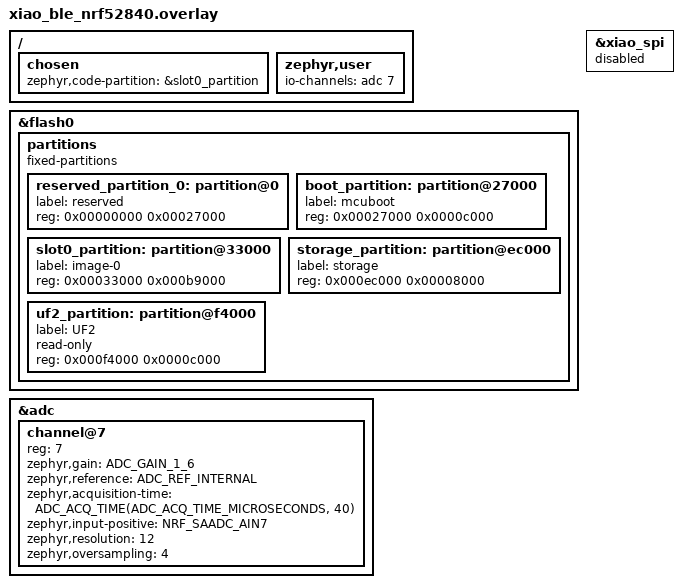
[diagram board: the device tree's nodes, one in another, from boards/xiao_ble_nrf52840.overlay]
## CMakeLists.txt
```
#
# Copyright (c) 2025 Nordic Semiconductor ASA
#
# SPDX-License-Identifier: LicenseRef-Nordic-5-Clause
#

cmake_minimum_required(VERSION 3.20.0)

find_package(Zephyr REQUIRED HINTS $ENV{ZEPHYR_BASE})
project(beacon)

# Board-specific battery path. Devicetree + Kconfig per board come from
# boards/<board>.overlay and boards/<board>.conf (picked up by Zephyr).
if(BOARD STREQUAL "xiao_ble" OR BOARD STREQUAL "promicro_nrf52840")
  set(BMT_BATTERY_SRC src/bmt_battery_${BOARD}.c)
else()
  message(FATAL_ERROR "Unsupported board '${BOARD}'. Use xiao_ble/nrf52840 or promicro_nrf52840/nrf52840/uf2.")
endif()

target_sources(app PRIVATE
    src/main.c
    src/bmt_auth.c
    src/bmt_beacon.c
    src/bmt_battery.c
    ${BMT_BATTERY_SRC}
)

# Wire protocol shared with the ESP-IDF apps (plain C header).
target_include_directories(app PRIVATE ${CMAKE_CURRENT_SOURCE_DIR}/../../components/bmt_protocol)
```

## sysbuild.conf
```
# [SECURITY] MCUboot - the Zephyr counterpart to Secure Boot V2 on ESP32 Tag.
# Single-slot mode: MCUboot only verifies the signature and boots
# slot0_partition. OTA over BLE is not supported yet (updates = re-flash
# the whole UF2 via the pre-installed Adafruit bootloader, see
# boards/<board>.overlay for why the layout is this way).
SB_CONFIG_BOOTLOADER_MCUBOOT=y
SB_CONFIG_MCUBOOT_MODE_SINGLE_APP=y
SB_CONFIG_BOOT_SIGNATURE_TYPE_ECDSA_P256=y
SB_CONFIG_BOOT_SIGNATURE_KEY_FILE="../../keys/bmt_tag_ecdsa_p256.pem"
```

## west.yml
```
# Freestanding Zephyr application manifest. Lets `west init -l .` set up
# a workspace that pulls in upstream Zephyr next to this app, without
# requiring the whole nRF Connect SDK.
manifest:
  self:
    path: apps/beacon_nrf52840
  remotes:
    - name: zephyrproject
      url-base: https://github.com/zephyrproject-rtos
  projects:
    - name: zephyr
      remote: zephyrproject
      revision: v4.0.0
      import:
        name-allowlist:
          - hal_nordic
          - mcuboot
          - cmsis
          - segger
          - tinycrypt
```

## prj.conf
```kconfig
# Common to every board. Board-specific Kconfig lives in
# boards/<board>.conf (merged automatically by Zephyr).

CONFIG_BT=y
CONFIG_BT_DEVICE_NAME="Test beacon"

# PSA Crypto (HMAC-SHA256) - needed by bmt_auth for epoch key rotation.
CONFIG_PSA_CRYPTO=y
CONFIG_PSA_WANT_ALG_HMAC=y
CONFIG_PSA_WANT_ALG_SHA_256=y
CONFIG_PSA_WANT_KEY_TYPE_HMAC=y

# [POWER] Drop the radio TX power from the default 0 dBm to -4 dBm. Cuts
# current at TX (also reduces the current pulse amplitude through the
# diode / cap - see the CR2032 sag discussion in README), at the cost of
# slightly shorter range - re-verify real-world distance after flashing.
CONFIG_BT_CTLR_TX_PWR_MINUS_4=y

# [POWER] Read the battery via the SAADC - channel per board in
# boards/<board>.overlay, conversion in src/bmt_battery_<board>.c.
CONFIG_ADC=y

# =====================================================================
# [POWER] Disable USB + CONSOLE + LOG - the largest single saving (~0.7-0.8 mA)
# =====================================================================
#
# Both boards use USB CDC-ACM as their console (no dedicated UART for
# debug), so just having CONFIG_CONSOLE=y drags in the full USB device
# stack and keeps it running forever: CONFIG_USB_DEVICE_STACK_NEXT +
# CONFIG_UDC_NRF. Because CONFIG_PM_DEVICE is not enabled, nothing
# suspends them -> current is drawn continuously EVEN AFTER the USB
# cable is unplugged.
#
# Measured on ProMicro (running from battery, USB unplugged, DT-9205A on
# the 200 mA range):
#   Full firmware (with USB / log)         1.7 mA
#   Empty firmware (no USB / log / BLE)    1.0 mA   <- the 0.7 mA diff is USB
#   Empty firmware + P0.13 LOW             0.9 mA   <- hardware floor, nothing to do
#
# DEBUG NOTE: turning this off means NO COM port and NO log. When you need
# logs, build with debug.conf to bring them back (see README, Build).
#
# Trying just CONFIG_LOG=n does NOT help - it only stops printing; the USB
# stack still initialises and runs. You must disable the console for the
# USB stack to actually be dropped from the build.
# THIS is the right switch (one line, instead of picking off each symbol).
# See zephyr/boards/common/usb/Kconfig.cdc_acm_serial.defconfig - the whole
#     if BOARD_SERIAL_BACKEND_CDC_ACM
#         config SERIAL                          default y
#         config CONSOLE                         default y
#         config USB_DEVICE_STACK_NEXT           default y if !MCUBOOT
#         config CDC_ACM_SERIAL_INITIALIZE_AT_BOOT  default y if !MCUBOOT
# block hangs off this switch, so disabling it drops the whole cluster.
#
# Turn off BOTH lines at the same time (do not split): CONFIG_LOG=n is
# what drops log_backend_uart.c from the build. Picking off
# CONFIG_CONSOLE / UART_CONSOLE / SERIAL=n one at a time does NOT work -
# .config still has USB_DEVICE_STACK_NEXT=y and UDC_NRF=y, and the build
# fails with "undefined reference __device_dts_ord_N" because the log /
# CDC-ACM backend is still compiled while its device was dropped from
# devicetree (hit on both boards).
CONFIG_BOARD_SERIAL_BACKEND_CDC_ACM=n
CONFIG_LOG=n
```

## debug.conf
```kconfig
# =====================================================================
# DEBUG BUILD - re-enable console / log over USB CDC-ACM
# =====================================================================
#
# prj.conf (production) DISABLES USB + console + log because they draw
# ~0.7-0.8 mA continuously even after the USB cable is unplugged - 
# see the full explanation in prj.conf.
#
# This file re-enables them so you can read logs for debugging. DO NOT
# USE FOR CURRENT MEASUREMENT: the reading will be ~0.7-0.8 mA higher
# than the real firmware.
#
# Build command (pick the board):
#   west build -b xiao_ble/nrf52840 -d build_debug . --pristine \
#       -- "-Dbeacon_nrf52840_EXTRA_CONF_FILE=debug.conf"
#   west build -b promicro_nrf52840/nrf52840/uf2 -d build_debug . --pristine \
#       -- "-Dbeacon_nrf52840_EXTRA_CONF_FILE=debug.conf"
#
# (The "beacon_nrf52840_" prefix is required - this is a sysbuild
#  multi-image build; without the prefix CMake configure will fail.)

# Re-enable the switch that prj.conf turned off. This drags in the
# whole cluster: SERIAL, CONSOLE, UART_CONSOLE, USB_DEVICE_STACK_NEXT,
# CDC_ACM_SERIAL_INITIALIZE_AT_BOOT (see prj.conf for the detail).
#
# NOTE: setting only CONFIG_CONSOLE=y / SERIAL=y without this line is
# USELESS - the console comes up but there is no UART device to send
# output to, so no COM port appears. (Been caught by this once on
# ProMicro.)
CONFIG_BOARD_SERIAL_BACKEND_CDC_ACM=y
CONFIG_LOG=y

# Bump the USB buffer pool to avoid "udc: Failed to allocate net_buf N"
# when USB control transactions and CDC-ACM log traffic overlap (after
# SUSPEND / RESUME).
CONFIG_UDC_BUF_POOL_SIZE=4096
CONFIG_UDC_BUF_COUNT=32
```

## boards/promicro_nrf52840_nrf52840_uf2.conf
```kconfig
# ProMicro nRF52840 - merged on top of prj.conf.

# [POWER] Turn off the soft switch that feeds power to the external VCC pin
# (P0.13) - saves ~0.1 mA. Needs the GPIO driver. See src/main.c and the
# overlay for the schematic detail.
CONFIG_GPIO=y

# =====================================================================
# [POWER] KEY DIFFERENCE VS XIAO - DC/DC regulator
# =====================================================================
#
# The nRF52840 has TWO separate DC/DC regulators for two power architectures:
#
#  - REG1 ("normal voltage"): used when VDD is fed by an external LDO that
#    has already stepped the rail down. This is the XIAO case (battery ->
#    BQ25101 -> LDO SGM2040 3.3 V). The XIAO board devicetree ships both
#    regulators enabled:
#         &reg0 { status = "okay"; };
#         &reg1 { regulator-initial-mode = <NRF5X_REG_MODE_DCDC>; };
#    plus the L3 10 uH inductor between DCC / DEC4.
#
#  - REG0 ("high voltage"): used when the battery wires directly into VDDH
# - the ProMicro / nice!nano v2 architecture.
#
# The ProMicro board in Zephyr does NOT configure reg0 / reg1 at all, so both
# stay at their defaults (REG1 in LDO mode, not DCDC).
#
# NOTE: the two legacy Kconfig symbols (CONFIG_SOC_DCDC_NRF52X / _HV) are
# DEPRECATED in this Zephyr version - DCDC must be enabled through
# DEVICETREE as shown above, not through prj.conf. (The
# CONFIG_BOARD_ENABLE_DCDC_HV symbol some ZMK guides mention is a ZMK-only
# thing and does not exist in upstream Zephyr.)
#
# NOT enabled in the initial version - DELIBERATE:
#   1) Cannot confirm this clone board has the inductor DCDC needs.
#   2) Real-world data from the ZMK community (issue zmkfirmware/zmk#2990)
#      shows enabling DC/DC HV mode on this class of board can INCREASE
#      current:
#         - Official nice!nano: +0.12-0.48 mA standby (up 20-25%)
#         - Clone boards: +1.30-1.32 mA (!!)
#      Suspicion: clones drop the inductor, so the switcher misbehaves
#      and draws more than the LDO would.
#
# => PLAN: measure current at the default first, then try enabling DCDC via
#    devicetree and remeasure. Only keep it if the numbers actually improve.

# =====================================================================
# [POWER] [TODO - not done, deliberate] Turn off unused peripherals
# =====================================================================
# The ProMicro board enables more peripherals than XIAO: i2c0, i2c1, pwm0,
# spi2, uart0 (see promicro_nrf52840_nrf52840_common.dts). This beacon app
# uses none of them, so disabling in principle would save a bit more.
#
# NOT done in the initial version: first want a WORKING image plus baseline
# current measurement, then disable one at a time AND remeasure to confirm
# each step. (Lesson from the XIAO variant: disabling SPI2 was thought to
# have hung the board, wasted hours debugging - the real culprit was
# flashing an unsigned app image. Since then, verify one config change at
# a time; don't change many things at once.)
#
# WATCH OUT: pwm0 is referenced by the "pwmleds" node (red_pwm_led);
# disabling pwm0 without handling that node will break the build.
```

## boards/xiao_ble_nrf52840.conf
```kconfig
# XIAO nRF52840 - merged on top of prj.conf. No extra symbols needed.
#
# [POWER] APPROACH A (continuous low-power advertising):
#  - CPU auto-sleeps (System ON idle) between transmits: Zephyr's idle
#    thread handles this - no config needed.
#  - DC/DC regulator: ALREADY ENABLED via the board devicetree (reg1 =
#    DCDC mode); nRF52's soc.c reads that property and calls
#    nrf_power_dcdcen_set(true) at boot, so NO extra config here.
#    (Verified against soc/nordic/nrf52/soc.c.)
#  - 1 s interval (bmt_config.h) and TX -4 dBm already set.
# => Approach A is close to optimal by construction; real current
#    measurement needs a Power Profiler (PPK2).
```

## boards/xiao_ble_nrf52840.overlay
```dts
/*
 * [SECURITY] MCUboot partition layout - Tag nRF52840.
 *
 * XIAO nRF52840 ships from the factory with the Adafruit UF2
 * bootloader (no SWD / J-Link is exposed; the only way to reflash
 * is UF2 mass storage). That bootloader lives at a FIXED high
 * address (0xF4000-0x100000, see nrf52840_partition_uf2_sdv7.dtsi
 * in Zephyr) and is jumped to directly by the CPU from
 * UICR.BOOTLOADERADDR at power-on - DO NOT touch this region, it
 * is the only recovery path if MCUboot / app is broken (you can
 * still drag-and-drop a fresh UF2 as usual).
 *
 * Once the Adafruit bootloader finishes it jumps to address
 * 0x27000 (the "Application" address hardcoded in the bootloader,
 * intended for SoftDevice s140 v7 - Zephyr does not use SoftDevice,
 * but must still boot at that fixed offset). So instead of putting
 * the app directly at 0x27000 as before, place MCUboot
 * (boot_partition) there - MCUboot becomes the "second-stage"
 * bootloader, chain-loaded by the Adafruit bootloader, then
 * verifies the signature and jumps to slot0_partition (the real
 * app).
 *
 * New layout:
 *   0x00000 - 0x27000  reserved         (unused, kept for historical meaning)
 *   0x27000 - 0x33000  boot_partition   (MCUboot, 48 KB)
 *   0x33000 - 0xEC000  slot0_partition  (app, ~741 KB - single-slot
 *                                        mode; no slot1 yet because
 *                                        BLE OTA is not implemented,
 *                                        updates = full UF2 reflash)
 *   0xEC000 - 0xF4000  storage_partition (32 KB, kept at old address)
 *   0xF4000 - 0x100000 uf2_partition    (Adafruit bootloader - UNTOUCHED)
 */

/delete-node/ &reserved_partition_0;
/delete-node/ &code_partition;
/delete-node/ &storage_partition;
/delete-node/ &boot_partition;

/ {
	chosen {
		zephyr,code-partition = &slot0_partition;
	};

	/* [POWER] Read battery via the ON-BOARD battery measurement
	 * path (for a cell wired into BAT+ / BAT- - LIR2032 3.6 V or
	 * LiPo).
	 *
	 * Different from reading VDD (only valid for a CR2032 wired
	 * straight to 3V3): when the cell feeds through BAT+ into the
	 * on-board regulator, VDD is pinned at ~3.3 V and does NOT
	 * reflect the true battery voltage. So the voltage at the
	 * BAT+ node must be read through the on-board 1M / 510k
	 * divider brought out to P0.31 (AIN7).
	 *
	 * P0.14 (VBAT_ENABLE, active-low) must be driven LOW to
	 * "close" the divider into the measurement path (see
	 * bmt_battery.c). Kept LOW for the whole lifetime - the
	 * divider leaks ~2.6 uA continuously, acceptable. MUST NOT be
	 * HIGH: P0.31 can then overshoot to 3.6 V (pin limit) - the
	 * official Seeed warning. */
	zephyr,user {
		io-channels = <&adc 7>;
	};
};

&flash0 {
	partitions {
		compatible = "fixed-partitions";
		#address-cells = <1>;
		#size-cells = <1>;

		reserved_partition_0: partition@0 {
			label = "reserved";
			reg = <0x00000000 0x00027000>;
		};

		boot_partition: partition@27000 {
			label = "mcuboot";
			reg = <0x00027000 0x0000c000>;
		};

		slot0_partition: partition@33000 {
			label = "image-0";
			reg = <0x00033000 0x000b9000>;
		};

		storage_partition: partition@ec000 {
			label = "storage";
			reg = <0x000ec000 0x00008000>;
		};

		uf2_partition: partition@f4000 {
			label = "UF2";
			read-only;
			reg = <0x000f4000 0x0000c000>;
		};
	};
};

/* [POWER] Disable SPI2 (xiao_spi) - the board enables it by
 * default but the firmware uses no SPI. (Historical note: first
 * disable attempt was thought to have hung the board, but the real
 * cause was flashing an UNSIGNED app image - MCUboot refused it.
 * Disabling SPI2 is harmless. Remember to flash with the
 * signed-merge output, see _fw_backup.) */
&xiao_spi {
	status = "disabled";
};

&adc {
	#address-cells = <1>;
	#size-cells = <0>;

	/* Channel 7 = P0.31 (AIN7) = output of the BAT+ on-board divider.
	 * Gain 1/6 + internal reference (0.6 V) -> input range 0..3.6 V,
	 * enough for the divided voltage (BAT+ 4.2 V / ~3.0 = ~1.4 V,
	 * comfortably inside the range). */
	channel@7 {
		reg = <7>;
		zephyr,gain = "ADC_GAIN_1_6";
		zephyr,reference = "ADC_REF_INTERNAL";
		/* The on-board divider has a source impedance of ~342 k
		 * (1037k || 510k) - VERY HIGH for the SAADC. Acquisition
		 * time MUST be 40 us (the SAADC maximum) so the
		 * sample-and-hold cap can charge fully -> accurate
		 * reading. At the DEFAULT 10 us, readings are off by
		 * several hundred mV (observed: firmware 3.88 V vs DMM
		 * 3.27 V). */
		zephyr,acquisition-time = <ADC_ACQ_TIME(ADC_ACQ_TIME_MICROSECONDS, 40)>;
		zephyr,input-positive = <NRF_SAADC_AIN7>;
		zephyr,resolution = <12>;
		zephyr,oversampling = <4>;
	};
};
```

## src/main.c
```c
#include <zephyr/kernel.h>
#include <zephyr/devicetree.h>
#include <zephyr/sys/printk.h>
#include <zephyr/logging/log.h>

#include <zephyr/bluetooth/bluetooth.h>

#include "bmt_auth.h"
#include "bmt_beacon.h"
#include "bmt_battery.h"

LOG_MODULE_REGISTER(bmt_main, LOG_LEVEL_INF);

#if DT_NODE_HAS_PROP(DT_PATH(zephyr_user), ext_vcc_gpios)
#include <zephyr/drivers/gpio.h>

/* [POWER] Soft switch that cuts power to the external VCC pin
 * (ProMicro P0.13) - full explanation in
 * boards/promicro_nrf52840_nrf52840_uf2.overlay.
 * Summary: the 3.3 V branch routed to the external pin is powered
 * by default (Zephyr does not declare a control pin, so it stays
 * in its reset state), wasting ~1 mA even when the app powers
 * nothing external. Boards without ext-vcc-gpios skip this. */
static const struct gpio_dt_spec ext_vcc =
    GPIO_DT_SPEC_GET(DT_PATH(zephyr_user), ext_vcc_gpios);

static void ext_vcc_off(void)
{
	if (!gpio_is_ready_dt(&ext_vcc))
	{
		LOG_ERR("ext-vcc GPIO not ready");
		return;
	}

	/* INACTIVE + active-high = drive LOW = MOSFET off.
	 * Safe for the MCU: this MOSFET only sits on the external VCC
	 * rail; the nRF52840 itself is powered separately via VDDH. */
	int err = gpio_pin_configure_dt(&ext_vcc, GPIO_OUTPUT_INACTIVE);
	if (err)
	{
		LOG_ERR("Failed to turn off external VCC (err %d)", err);
		return;
	}
	LOG_INF("External VCC pin turned off");
}
#else
static void ext_vcc_off(void)
{
}
#endif

static void bt_ready(int err)
{
	if (err)
	{
		LOG_ERR("Bluetooth init failed (err %d)", err);
		return;
	}
	LOG_INF("Bluetooth initialized");

	/* MUST be called before bmt_beacon_start() - the beacon needs
	 * the HMAC key ready so it can compute mac16 for the very
	 * first ADV. */
	bmt_auth_init();

	err = bmt_beacon_start();
	if (err)
	{
		LOG_ERR("bmt_beacon_start failed (err %d)", err);
		return;
	}
	LOG_INF("BMT Tag beacon started");
}

int main(void)
{
	printk("=== BMT Tag (nRF52840) starting ===\n");

	/* As EARLY as possible - every millisecond of delay lets current
	 * waste on the external VCC rail. */
	ext_vcc_off();

	/* Battery reading has nothing to do with BLE, start it in
	 * parallel with bt_enable. */
	int batt_err = bmt_battery_init();
	if (batt_err)
	{
		LOG_ERR("bmt_battery_init failed (err %d)", batt_err);
	}

	int err = bt_enable(bt_ready);
	if (err)
	{
		LOG_ERR("bt_enable failed (err %d)", err);
	}
	return 0;
}
```

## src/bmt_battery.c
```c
#include "bmt_battery.h"

#include <zephyr/kernel.h>
#include <zephyr/device.h>
#include <zephyr/devicetree.h>
#include <zephyr/drivers/adc.h>
#include <zephyr/logging/log.h>

#include "bmt_battery_board.h"

LOG_MODULE_REGISTER(bmt_battery, LOG_LEVEL_INF);

static const struct adc_dt_spec battery_adc = ADC_DT_SPEC_GET_BY_IDX(DT_PATH(zephyr_user), 0);

/* Voltage -> percent lookup for Li-ion (LIR2032 / LiPo). The Li-ion
 * SoC-vs-voltage curve is strongly non-linear, so a single linear
 * formula would be wrong across the range - use a table and
 * interpolate between adjacent points. 4200 mV = 100% (full),
 * 3300 mV = 0% (safe cutoff; below this the cell degrades).
 * Curve from the Tjoms99 library and the Nordic SoC blog. */
typedef struct
{
	uint16_t mv;
	uint8_t pct;
} batt_point_t;

static const batt_point_t BATT_CURVE[] = {
    {4200, 100},
    {4110, 90},
    {4020, 80},
    {3930, 70},
    {3840, 60},
    {3750, 50},
    {3660, 40},
    {3570, 30},
    {3480, 20},
    {3390, 10},
    {3300, 0},
};
#define BATT_CURVE_N (sizeof(BATT_CURVE) / sizeof(BATT_CURVE[0]))

#define BMT_BATT_LOG_INTERVAL_SEC 30

static struct k_timer batt_log_timer;
static struct k_work batt_log_work;

/* Cached % - the beacon reads this and embeds it in each ADV
 * (instead of hitting the ADC per packet). Refreshed by the work
 * handler (30 s) and once synchronously during init. */
static uint8_t s_last_percent = 0;

uint8_t bmt_battery_last_percent(void)
{
	return s_last_percent;
}

int bmt_battery_read_mv(void)
{
	int16_t raw = 0;
	struct adc_sequence sequence = {
	    .buffer = &raw,
	    .buffer_size = sizeof(raw),
	};

	int err = adc_sequence_init_dt(&battery_adc, &sequence);
	if (err < 0)
	{
		LOG_ERR("adc_sequence_init_dt failed (%d)", err);
		return err;
	}

	err = adc_read_dt(&battery_adc, &sequence);
	if (err < 0)
	{
		LOG_ERR("adc_read_dt failed (%d)", err);
		return err;
	}

	int32_t adc_mv = raw;
	err = adc_raw_to_millivolts_dt(&battery_adc, &adc_mv);
	if (err < 0)
	{
		LOG_ERR("adc_raw_to_millivolts_dt failed (%d)", err);
		return err;
	}

	return bmt_battery_board_adc_to_mv(adc_mv);
}

uint8_t bmt_battery_percent(int mv)
{
	if (mv >= BATT_CURVE[0].mv)
		return 100;
	if (mv <= BATT_CURVE[BATT_CURVE_N - 1].mv)
		return 0;

	for (size_t i = 0; i < BATT_CURVE_N - 1; i++)
	{
		uint16_t hi = BATT_CURVE[i].mv;
		uint16_t lo = BATT_CURVE[i + 1].mv;
		if (mv <= hi && mv >= lo)
		{
			/* Linear interpolation between the two adjacent points. */
			int pct_hi = BATT_CURVE[i].pct;
			int pct_lo = BATT_CURVE[i + 1].pct;
			return (uint8_t)(pct_lo + ((mv - lo) * (pct_hi - pct_lo)) / (hi - lo));
		}
	}
	return 0;
}

static void batt_log_work_handler(struct k_work* work)
{
	ARG_UNUSED(work);

	int mv = bmt_battery_read_mv();
	if (mv < 0)
	{
		LOG_ERR("Battery read failed (%d)", mv);
		return;
	}
	s_last_percent = bmt_battery_percent(mv);
	LOG_INF("[BATTERY] %s=%d mV (~%u%%) %s", bmt_battery_board_rail, mv, s_last_percent,
	        bmt_battery_is_charging() ? "[CHARGING]" : "");
}

static void batt_log_timer_handler(struct k_timer* timer)
{
	/* k_timer callback runs in ISR context; adc_read may block,
	 * so hand it off to the workqueue. */
	ARG_UNUSED(timer);
	k_work_submit(&batt_log_work);
}

int bmt_battery_init(void)
{
	int err = bmt_battery_board_init();
	if (err < 0)
	{
		return err;
	}

	if (!adc_is_ready_dt(&battery_adc))
	{
		LOG_ERR("ADC device %s not ready", battery_adc.dev->name);
		return -ENODEV;
	}

	err = adc_channel_setup_dt(&battery_adc);
	if (err < 0)
	{
		LOG_ERR("adc_channel_setup_dt failed (%d)", err);
		return err;
	}

	LOG_INF("Battery ADC (%s) ready", bmt_battery_board_rail);

	/* Synchronous read once so s_last_percent has a valid value
	 * BEFORE the beacon starts advertising (build_adv_data reads
	 * bmt_battery_last_percent). */
	int mv0 = bmt_battery_read_mv();
	if (mv0 >= 0)
		s_last_percent = bmt_battery_percent(mv0);

	k_work_init(&batt_log_work, batt_log_work_handler);
	k_timer_init(&batt_log_timer, batt_log_timer_handler, NULL);
	k_timer_start(&batt_log_timer, K_SECONDS(BMT_BATT_LOG_INTERVAL_SEC),
	              K_SECONDS(BMT_BATT_LOG_INTERVAL_SEC));

	/* Print once at boot as well. */
	k_work_submit(&batt_log_work);

	return 0;
}
```

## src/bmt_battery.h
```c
#pragma once

#include <stdbool.h>
#include <stdint.h>

/* Initialise the board's battery-measurement path and start the
 * periodic read. The ADC channel comes from the zephyr,user node in
 * boards/<board>.overlay; board-specific setup lives in
 * bmt_battery_<board>.c. */
int bmt_battery_init(void);

/* Read the actual battery voltage (compensating for the board's
 * divider), in mV. Returns < 0 on error. */
int bmt_battery_read_mv(void);

/* Estimate remaining battery percentage from voltage using a Li-ion
 * lookup curve (interpolated, see BATT_CURVE in bmt_battery.c). 0-100. */
uint8_t bmt_battery_percent(int mv);

/* true when the charger IC is charging. Always false on boards that
 * do not expose a charge-status pin (ProMicro). */
bool bmt_battery_is_charging(void);

/* Cached % from the most recent periodic read - used by the beacon
 * to embed in each ADV payload without re-reading the ADC. Refreshed
 * by a 30 s timer in bmt_battery.c and once synchronously at init. */
uint8_t bmt_battery_last_percent(void);
```

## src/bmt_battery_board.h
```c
#pragma once

#include <stdint.h>

/* Board hooks for bmt_battery.c, implemented by exactly one
 * src/bmt_battery_<board>.c (selected in CMakeLists.txt). */

/* Name of the measured rail, for logs ("BAT+", "VDDH"). */
extern const char* const bmt_battery_board_rail;

/* Board GPIO setup needed before the ADC reads anything. */
int bmt_battery_board_init(void);

/* Convert the ADC pin voltage back to the real battery voltage. */
int bmt_battery_board_adc_to_mv(int32_t adc_mv);
```

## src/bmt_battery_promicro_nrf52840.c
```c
#include "bmt_battery.h"
#include "bmt_battery_board.h"

/* ProMicro nRF52840 / nice!nano v2: the battery wires directly into
 * the nRF52840's VDDH (high-voltage mode). Read via the SAADC's
 * internal VDDHDIV5 (see the overlay) - no external divider and no
 * GPIO enable needed (unlike XIAO, which needs P0.31 + P0.14). */
const char* const bmt_battery_board_rail = "VDDH";

/* VDDHDIV5: raw reading = VDDH / 5, so multiply by 5 to recover the
 * actual battery voltage. */
#define BMT_BATT_VDDH_DIVIDER 5

int bmt_battery_board_init(void)
{
	return 0;
}

int bmt_battery_board_adc_to_mv(int32_t adc_mv)
{
	return adc_mv * BMT_BATT_VDDH_DIVIDER;
}

bool bmt_battery_is_charging(void)
{
	/* This board does NOT route the charger IC's ~CHG pin to any
	 * readable GPIO - unlike XIAO (P0.17).
	 *
	 * Could be inferred indirectly from VDDH itself: when USB is
	 * connected, VDDH climbs to ~5 V, well above a full battery
	 * (4.2 V). Not implemented - need a real board to calibrate
	 * the threshold first. */
	return false;
}
```

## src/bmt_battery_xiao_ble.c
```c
#include "bmt_battery.h"
#include "bmt_battery_board.h"

#include <zephyr/device.h>
#include <zephyr/devicetree.h>
#include <zephyr/drivers/gpio.h>
#include <zephyr/logging/log.h>

LOG_MODULE_DECLARE(bmt_battery);

/* [POWER] XIAO nRF52840: read the battery over the BAT+ / BAT- rail
 * (LIR2032 3.6 V or LiPo).
 *
 * Why NOT read VDD directly: when the cell feeds through the
 * on-board regulator, VDD is pinned at ~3.3 V regardless of whether
 * the cell is at 4.2 V or 3.4 V - so reading VDD tells us nothing
 * useful. Read the voltage at the BAT+ node through the on-board
 * 1M/510k divider brought out to P0.31 (AIN7, see the overlay).
 * Formula and resistor values follow the
 * Tjoms99/xiao_sense_nrf52840_battery_lib community library
 * (verified on real hardware).
 *
 * (If later switching back to a CR2032 wired straight to 3V3,
 * change this to read NRF_SAADC_VDD in the overlay and drop the
 * divider - different supply, different measurement path.) */
const char* const bmt_battery_board_rail = "BAT+";

/* On-board divider: BAT+ --[R1]-- P0.31 --[R2]-- (P0.14 pulls GND).
 * V_bat = V_adc * (R1 + R2) / R2. Nominal 1M / 510k; R1 is set to
 * 1037k per the empirical calibration from the reference library
 * (resistor tolerance). For higher accuracy, measure real V_bat
 * with a DMM and recompute R1. */
#define BMT_BATT_R1_KOHM 1037
#define BMT_BATT_R2_KOHM 510

/* P0.14 = VBAT_ENABLE (active-low): drive LOW to close the divider
 * into the measurement path.
 * P0.17 = charge status (LOW while charging). */
static const struct device* gpio0 = DEVICE_DT_GET(DT_NODELABEL(gpio0));
#define BMT_BATT_ENABLE_PIN 14
#define BMT_BATT_CHARGE_STAT_PIN 17

int bmt_battery_board_init(void)
{
	if (!device_is_ready(gpio0))
	{
		LOG_ERR("gpio0 not ready");
		return -ENODEV;
	}

	/* P0.14 VBAT_ENABLE active-low: OUTPUT_ACTIVE -> drive LOW ->
	 * close the divider into the measurement path. Keep LOW for
	 * the whole lifetime (see the overlay note) - MUST NOT be
	 * HIGH (even briefly): Seeed officially warns that P0.31 can
	 * overshoot the ADC input limit when P0.14 is HIGH. */
	int err = gpio_pin_configure(gpio0, BMT_BATT_ENABLE_PIN,
	                             GPIO_OUTPUT_ACTIVE | GPIO_ACTIVE_LOW);
	if (err < 0)
	{
		LOG_ERR("config VBAT_ENABLE (P0.14) failed (%d)", err);
		return err;
	}

	/* P0.17 charge-status: INPUT to read the charge state. */
	err = gpio_pin_configure(gpio0, BMT_BATT_CHARGE_STAT_PIN, GPIO_INPUT);
	if (err < 0)
	{
		LOG_ERR("config CHARGE_STAT (P0.17) failed (%d)", err);
		return err;
	}
	return 0;
}

int bmt_battery_board_adc_to_mv(int32_t adc_mv)
{
	/* Reverse the divider ratio to recover the real BAT+ voltage. */
	return (adc_mv * (BMT_BATT_R1_KOHM + BMT_BATT_R2_KOHM)) / BMT_BATT_R2_KOHM;
}

bool bmt_battery_is_charging(void)
{
	/* P0.17 LOW = charging (charger IC pulls it down). */
	return gpio_pin_get(gpio0, BMT_BATT_CHARGE_STAT_PIN) == 0;
}
```

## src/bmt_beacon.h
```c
#pragma once

#include <stdbool.h>
#include <stdint.h>

/* Create the 500 ms sequence timer and start advertising.
 * MUST be called AFTER a successful bt_enable() and after
 * bmt_auth_init() has run. */
int bmt_beacon_start(void);

/* Getters (debug / status). */
uint8_t bmt_beacon_sequence(void);
uint16_t bmt_beacon_last_mac16(void);
bool bmt_beacon_is_active(void);
```
